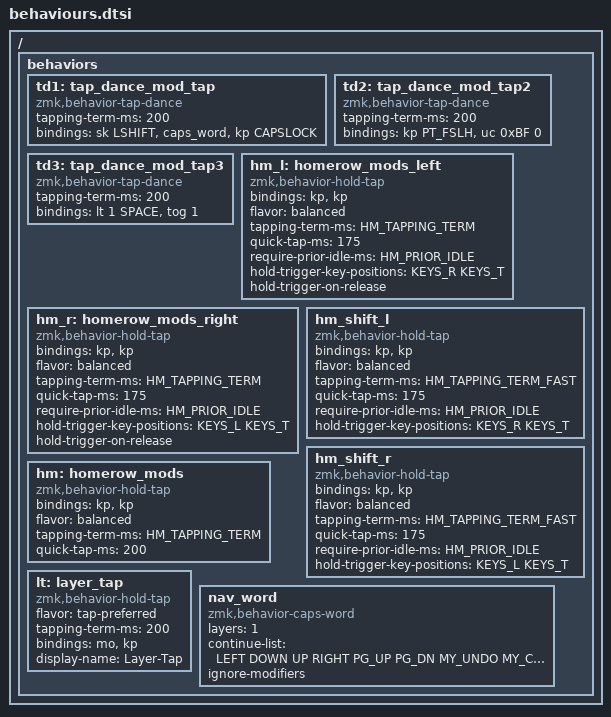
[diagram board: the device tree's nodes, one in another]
//	Make sure settings.dtsi is sourced before this file

/*
 * 	 Use this file to add all your behaviors
 */



/ {
        behaviors {
                td1: tap_dance_mod_tap {
                    compatible = "zmk,behavior-tap-dance";
                    #binding-cells = <0>;
                    tapping-term-ms = <200>;
                    bindings = <&sk LSHIFT>, <&caps_word>, <&kp CAPSLOCK>;
                };

                td2: tap_dance_mod_tap2 {
                    compatible = "zmk,behavior-tap-dance";
                    #binding-cells = <0>;
                    tapping-term-ms = <200>;
                    bindings = <&kp PT_FSLH >, <&uc 0xBF 0>;
                };
                td3: tap_dance_mod_tap3 {
                  compatible = "zmk,behavior-tap-dance";
                  #binding-cells = <0>;
                  tapping-term-ms = <200>;
                  bindings = <&lt 1 SPACE>, <&tog 1>;
                };

        // Positional Homerow mods
        // Homerow mods that prevent accidental activations when rolling keys,
        // such as when typing `st` or `ne` on colemak-dh layouts or `as` on
        // qwerty.
        //
        // Works by only allowing a mod to activate within tapping-term if
        // it's on the opposite side of the keyboard or on the same side thumb
        // keys.

        // Further optimization using urob's timerless homerow mods method:
        // https://github.com/urob/zmk-config#timeless-homerow-mods
        hm_l: homerow_mods_left {
            compatible = "zmk,behavior-hold-tap";
            #binding-cells = <2>;
            bindings = <&kp>,  <&kp>;

            flavor = "balanced";
            tapping-term-ms = <HM_TAPPING_TERM>;
            quick-tap-ms = <175>;                // repeat on tap-into-hold
            require-prior-idle-ms = <HM_PRIOR_IDLE>;

            hold-trigger-key-positions = <KEYS_R KEYS_T>;
            hold-trigger-on-release;
        };

        hm_r: homerow_mods_right {
            compatible = "zmk,behavior-hold-tap";
            #binding-cells = <2>;
            bindings = <&kp>, <&kp>;

            flavor = "balanced";
            tapping-term-ms = <HM_TAPPING_TERM>;
            quick-tap-ms = <175>;
            require-prior-idle-ms = <HM_PRIOR_IDLE>;

            hold-trigger-key-positions = <KEYS_L KEYS_T>;
            hold-trigger-on-release;
        };


        // Positional Homerow mods for shift
        // Use faster tapping term and disable some features that may
        // cause false negatives.
        hm_shift_l: hm_shift_l {
            compatible = "zmk,behavior-hold-tap";
            #binding-cells = <2>;
            bindings = <&kp>, <&kp>;

            flavor = "balanced";
            tapping-term-ms = <HM_TAPPING_TERM_FAST>;
            quick-tap-ms = <175>;
            require-prior-idle-ms = <HM_PRIOR_IDLE>;

            hold-trigger-key-positions = <KEYS_R KEYS_T>;
            // hold-trigger-on-release;
        };

        hm_shift_r: hm_shift_r {
            compatible = "zmk,behavior-hold-tap";
            #binding-cells = <2>;
            bindings = <&kp>, <&kp>;

            flavor = "balanced";
            tapping-term-ms = <HM_TAPPING_TERM_FAST>;
            quick-tap-ms = <175>;
            require-prior-idle-ms = <HM_PRIOR_IDLE>;

            hold-trigger-key-positions = <KEYS_L KEYS_T>;
            // hold-trigger-on-release;
        };

        /*
         * Non-Positional Homerow Mods
         * Used for &mm_grescm_gui behavior on left hand.
         *
         * Usage: &hm LSHFT T
         * Tap: T
         * Tap-Tap-Hold: Repeat T
         * Hold: LSHIFT
         */
        hm: homerow_mods {
            compatible = "zmk,behavior-hold-tap";
            #binding-cells = <2>;
            bindings = <&kp>, <&kp>;

            flavor = "balanced";
            tapping-term-ms = <HM_TAPPING_TERM>;
            quick-tap-ms = <200>;
        };
        lt: layer_tap {
            compatible = "zmk,behavior-hold-tap";
            #binding-cells = <2>;
            flavor = "tap-preferred";
            tapping-term-ms = <200>;
            bindings = <&mo>, <&kp>;
            display-name = "Layer-Tap";
        };
        ///nav_word: nav_word {
            ///compatible = "zmk,behavior-auto-layer";
            ///#binding-cells = <1>;
            ///continue-list = <LEFT DOWN UP RIGHT PG_DN PG_UP>;
            ///ignore-modifiers;
        ///};
        nav_word: nav_word {
            compatible = "zmk,behavior-caps-word";
            #binding-cells = <0>;
            layers = <1>;
            continue-list = <LEFT DOWN UP RIGHT PG_UP PG_DN MY_UNDO MY_CUT MY_COPY MY_PASTEp >;
            ignore-modifiers;  // modifiers don't deactivate the layer
        };
//        num_word: num_word {
//            compatible = "zmk,behavior-caps-word";
//            #binding-cells = <0>;
//            layers = <1>; // Replace NUM by index of numbers layer
//            continue-list = <BSPC DEL DOT COMMA PLUS MINUS STAR FSLH EQUAL>;
//				};
        };
};
